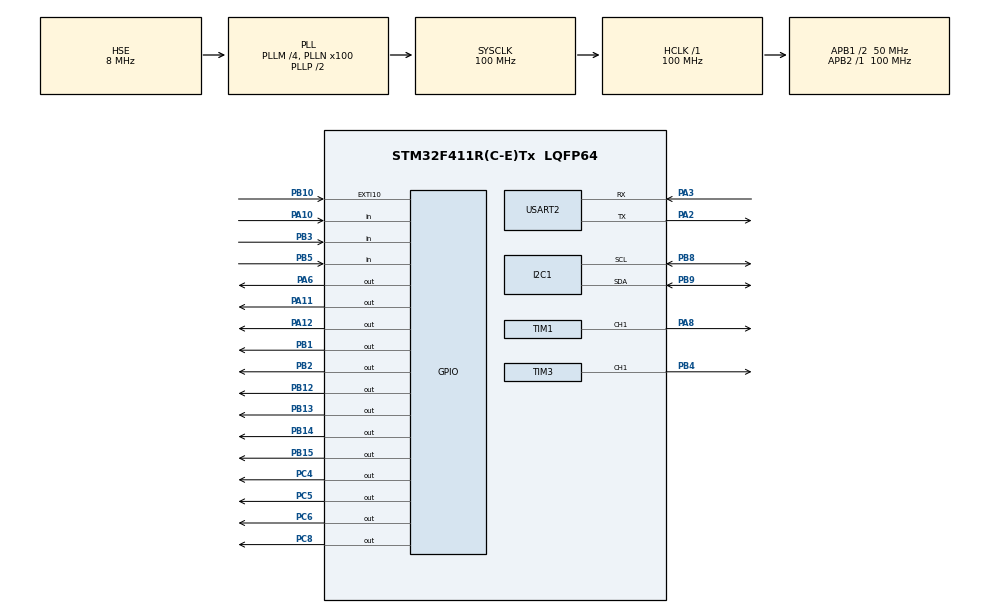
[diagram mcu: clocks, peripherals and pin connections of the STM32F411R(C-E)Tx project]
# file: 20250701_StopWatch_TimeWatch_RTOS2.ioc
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FREERTOS.Tasks01=defaultTask,0,128,StartDefaultTask,Default,NULL,Dynamic,NULL,NULL;ListenerTask,0,128,ListenerThread,Default,NULL,Dynamic,NULL,NULL;ControllerTask,0,128,ControllerThread,Default,NULL,Dynamic,NULL,NULL;PresenterTask,0,128,PresenterThread,Default,NULL,Dynamic,NULL,NULL
FREERTOS.configUSE_NEWLIB_REENTRANT=1
Mcu.Family=STM32F4
Mcu.Name=STM32F411R(C-E)Tx
Mcu.Package=LQFP64
NVIC.EXTI15_10_IRQn=true\:5\:0\:false\:false\:true\:true\:true\:true\:true
NVIC.PriorityGroup=NVIC_PRIORITYGROUP_4
NVIC.TIM1_TRG_COM_TIM11_IRQn=true\:15\:0\:false\:false\:true\:false\:false\:true\:true
NVIC.TIM2_IRQn=true\:5\:0\:false\:false\:true\:true\:true\:true\:true
NVIC.TIM4_IRQn=true\:5\:0\:false\:false\:true\:true\:true\:true\:true
NVIC.TimeBase=TIM1_TRG_COM_TIM11_IRQn
NVIC.TimeBaseIP=TIM11
NVIC.USART2_IRQn=true\:5\:0\:false\:false\:true\:true\:true\:true\:true
PA10.Signal=GPIO_Input
PA11.Signal=GPIO_Output
PA12.Signal=GPIO_Output
PA13.Mode=Serial_Wire
PA13.Signal=SYS_JTMS-SWDIO
PA14.Mode=Serial_Wire
PA14.Signal=SYS_JTCK-SWCLK
PA2.Mode=Asynchronous
PA2.Signal=USART2_TX
PA3.Mode=Asynchronous
PA3.Signal=USART2_RX
PA6.Signal=GPIO_Output
PA8.Signal=S_TIM1_CH1
PB1.Signal=GPIO_Output
PB10.GPIO_ModeDefaultEXTI=GPIO_MODE_IT_RISING_FALLING
PB10.Signal=GPXTI10
PB12.Signal=GPIO_Output
PB13.Signal=GPIO_Output
PB14.Signal=GPIO_Output
PB15.Signal=GPIO_Output
PB2.Signal=GPIO_Output
PB3.Signal=GPIO_Input
PB4.Signal=S_TIM3_CH1
PB5.Signal=GPIO_Input
PB8.Mode=I2C
PB8.Signal=I2C1_SCL
PB9.Mode=I2C
PB9.Signal=I2C1_SDA
PC4.Signal=GPIO_Output
PC5.Signal=GPIO_Output
PC6.Signal=GPIO_Output
PC8.Signal=GPIO_Output
PH0\ -\ OSC_IN.Mode=HSE-External-Oscillator
PH0\ -\ OSC_IN.Signal=RCC_OSC_IN
PH1\ -\ OSC_OUT.Mode=HSE-External-Oscillator
PH1\ -\ OSC_OUT.Signal=RCC_OSC_OUT
ProjectManager.HeapSize=0x200
ProjectManager.StackSize=0x400
ProjectManager.TargetToolchain=STM32CubeIDE
RCC.48MHZClocksFreq_Value=50000000
RCC.AHBFreq_Value=100000000
RCC.APB1CLKDivider=RCC_HCLK_DIV2
RCC.APB1Freq_Value=50000000
RCC.APB1TimFreq_Value=100000000
RCC.APB2Freq_Value=100000000
RCC.APB2TimFreq_Value=100000000
RCC.CortexFreq_Value=100000000
RCC.HCLKFreq_Value=100000000
RCC.HSE_VALUE=8000000
RCC.HSI_VALUE=16000000
RCC.LSE_VALUE=32768
RCC.PLLM=4
RCC.PLLN=100
RCC.PLLSourceVirtual=RCC_PLLSOURCE_HSE
RCC.SYSCLKFreq_VALUE=100000000
RCC.SYSCLKSource=RCC_SYSCLKSOURCE_PLLCLK
RCC.VCOOutputFreq_Value=200000000
SH.S_TIM1_CH1.0=TIM1_CH1,PWM Generation1 CH1
SH.S_TIM3_CH1.0=TIM3_CH1,PWM Generation1 CH1
TIM1.AutoReloadPreload=TIM_AUTORELOAD_PRELOAD_ENABLE
TIM1.Channel-PWM\ Generation1\ CH1=TIM_CHANNEL_1
TIM1.Period=100-1
TIM1.Prescaler=10000-1
TIM1.Pulse-PWM\ Generation1\ CH1=50-1
TIM2.Period=1000-1
TIM2.Prescaler=100-1
TIM3.AutoReloadPreload=TIM_AUTORELOAD_PRELOAD_ENABLE
TIM3.Channel-PWM\ Generation1\ CH1=TIM_CHANNEL_1
TIM3.Period=1000-1
TIM3.Prescaler=100-1
TIM4.AutoReloadPreload=TIM_AUTORELOAD_PRELOAD_ENABLE
TIM4.Period=1000-1
TIM4.Prescaler=100-1
TIM5.AutoReloadPreload=TIM_AUTORELOAD_PRELOAD_ENABLE
TIM5.Prescaler=100-1
USART2.VirtualMode=VM_ASYNC
VP_FREERTOS_VS_CMSIS_V1.Mode=CMSIS_V1
VP_SYS_VS_tim11.Mode=TIM11
VP_TIM2_VS_ClockSourceINT.Mode=Internal
VP_TIM3_VS_ClockSourceINT.Mode=Internal
VP_TIM4_VS_ClockSourceINT.Mode=Internal
VP_TIM5_VS_ClockSourceINT.Mode=Internal
board=custom

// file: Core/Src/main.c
/* USER CODE BEGIN Header */
/**
  ******************************************************************************
  * @file           : main.c
  * @brief          : Main program body
  ******************************************************************************
  * @attention
  *
  * Copyright (c) 2025 STMicroelectronics.
  * All rights reserved.
  *
  * This software is licensed under terms that can be found in the LICENSE file
  * in the root directory of this software component.
  * If no LICENSE file comes with this software, it is provided AS-IS.
  *
  ******************************************************************************
  */
/* USER CODE END Header */
#include "main.h"
#include "cmsis_os.h"
#include "i2c.h"
#include "tim.h"
#include "usart.h"
#include "gpio.h"

/* USER CODE BEGIN Includes */
#include "ap_main.h"
/* USER CODE END Includes */

void SystemClock_Config(void);
void MX_FREERTOS_Init(void);

int main(void)
{

  /* MCU Configuration--------------------------------------------------------*/

  /* Reset of all peripherals, Initializes the Flash interface and the Systick. */
  HAL_Init();

  /* Configure the system clock */
  SystemClock_Config();

  /* Initialize all configured peripherals */
  MX_GPIO_Init();
  MX_TIM2_Init();
  MX_USART2_UART_Init();
  MX_I2C1_Init();
  MX_TIM3_Init();
  MX_TIM1_Init();
  MX_TIM4_Init();
  MX_TIM5_Init();
  /* USER CODE BEGIN 2 */
  ap_init();
  /* USER CODE END 2 */

  /* Call init function for freertos objects (in cmsis_os2.c) */
  MX_FREERTOS_Init();

  /* Start scheduler */
  osKernelStart();

  /* We should never get here as control is now taken by the scheduler */

  /* Infinite loop */
  /* USER CODE BEGIN WHILE */
  while (1)
  {
	  ap_main();

    /* USER CODE END WHILE */

  }
}

void SystemClock_Config(void)
{
  RCC_OscInitTypeDef RCC_OscInitStruct = {0};
  RCC_ClkInitTypeDef RCC_ClkInitStruct = {0};

  /** Configure the main internal regulator output voltage
  */
  __HAL_RCC_PWR_CLK_ENABLE();
  __HAL_PWR_VOLTAGESCALING_CONFIG(PWR_REGULATOR_VOLTAGE_SCALE1);

  /** Initializes the RCC Oscillators according to the specified parameters
  * in the RCC_OscInitTypeDef structure.
  */
  RCC_OscInitStruct.OscillatorType = RCC_OSCILLATORTYPE_HSE;
  RCC_OscInitStruct.HSEState = RCC_HSE_ON;
  RCC_OscInitStruct.PLL.PLLState = RCC_PLL_ON;
  RCC_OscInitStruct.PLL.PLLSource = RCC_PLLSOURCE_HSE;
  RCC_OscInitStruct.PLL.PLLM = 4;
  RCC_OscInitStruct.PLL.PLLN = 100;
  RCC_OscInitStruct.PLL.PLLP = RCC_PLLP_DIV2;
  RCC_OscInitStruct.PLL.PLLQ = 4;
  if (HAL_RCC_OscConfig(&RCC_OscInitStruct) != HAL_OK)
  {
    Error_Handler();
  }

  /** Initializes the CPU, AHB and APB buses clocks
  */
  RCC_ClkInitStruct.ClockType = RCC_CLOCKTYPE_HCLK|RCC_CLOCKTYPE_SYSCLK
                              |RCC_CLOCKTYPE_PCLK1|RCC_CLOCKTYPE_PCLK2;
  RCC_ClkInitStruct.SYSCLKSource = RCC_SYSCLKSOURCE_PLLCLK;
  RCC_ClkInitStruct.AHBCLKDivider = RCC_SYSCLK_DIV1;
  RCC_ClkInitStruct.APB1CLKDivider = RCC_HCLK_DIV2;
  RCC_ClkInitStruct.APB2CLKDivider = RCC_HCLK_DIV1;

  if (HAL_RCC_ClockConfig(&RCC_ClkInitStruct, FLASH_LATENCY_3) != HAL_OK)
  {
    Error_Handler();
  }
}

void HAL_TIM_PeriodElapsedCallback(TIM_HandleTypeDef *htim)
{
  if (htim->Instance == TIM11)
  {
    HAL_IncTick();
  }

  if(htim->Instance == TIM2) {
     FND_DispDataCallBack();

     TimeWatch_IncTimeCallBack();
     StopWatch_IncTimeCallBack();
  }
}

void Error_Handler(void)
{
  __disable_irq();
  while (1)
  {
  }
}

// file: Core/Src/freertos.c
/* USER CODE BEGIN Header */
/**
  ******************************************************************************
  * File Name          : freertos.c
  * Description        : Code for freertos applications
  ******************************************************************************
  * @attention
  *
  * Copyright (c) 2025 STMicroelectronics.
  * All rights reserved.
  *
  * This software is licensed under terms that can be found in the LICENSE file
  * in the root directory of this software component.
  * If no LICENSE file comes with this software, it is provided AS-IS.
  *
  ******************************************************************************
  */
/* USER CODE END Header */

#include "FreeRTOS.h"
#include "task.h"
#include "main.h"
#include "cmsis_os.h"

osThreadId defaultTaskHandle;
osThreadId ListenerTaskHandle;
osThreadId ControllerTaskHandle;
osThreadId PresenterTaskHandle;

/* USER CODE BEGIN FunctionPrototypes */
//void HAL_TIM_PeriodElapsedCallback(TIM_HandleTypeDef *htim)
//{
//   if(htim->Instance == TIM2) {
//      FND_DispDataCallBack();
//
//      TimeWatch_IncTimeCallBack();
//      StopWatch_IncTimeCallBack();
//   }
//}

//void HAL_UART_RxCpltCallback(UART_HandleTypeDef *huart)
//{
//   if (huart->Instance == USART2) {
//      Listener_UartCallBack();
//   }
//}

/* USER CODE END FunctionPrototypes */

void StartDefaultTask(void const * argument);
void ListenerThread(void const * argument);
void ControllerThread(void const * argument);
void PresenterThread(void const * argument);

void MX_FREERTOS_Init(void); /* (MISRA C 2004 rule 8.1) */

/* GetIdleTaskMemory prototype (linked to static allocation support) */
void vApplicationGetIdleTaskMemory( StaticTask_t **ppxIdleTaskTCBBuffer, StackType_t **ppxIdleTaskStackBuffer, uint32_t *pulIdleTaskStackSize );

/* USER CODE BEGIN GET_IDLE_TASK_MEMORY */
static StaticTask_t xIdleTaskTCBBuffer;
static StackType_t xIdleStack[configMINIMAL_STACK_SIZE];

void vApplicationGetIdleTaskMemory( StaticTask_t **ppxIdleTaskTCBBuffer, StackType_t **ppxIdleTaskStackBuffer, uint32_t *pulIdleTaskStackSize )
{
  *ppxIdleTaskTCBBuffer = &xIdleTaskTCBBuffer;
  *ppxIdleTaskStackBuffer = &xIdleStack[0];
  *pulIdleTaskStackSize = configMINIMAL_STACK_SIZE;
  /* place for user code */
}
/* USER CODE END GET_IDLE_TASK_MEMORY */

void MX_FREERTOS_Init(void) {
  /* USER CODE BEGIN Init */
	Model_Init();
  /* USER CODE END Init */

  /* Create the thread(s) */
  /* definition and creation of defaultTask */
  osThreadDef(defaultTask, StartDefaultTask, osPriorityNormal, 0, 128);
  defaultTaskHandle = osThreadCreate(osThread(defaultTask), NULL);

  /* definition and creation of ListenerTask */
  osThreadDef(ListenerTask, ListenerThread, osPriorityNormal, 0, 128);
  ListenerTaskHandle = osThreadCreate(osThread(ListenerTask), NULL);

  /* definition and creation of ControllerTask */
  osThreadDef(ControllerTask, ControllerThread, osPriorityNormal, 0, 128);
  ControllerTaskHandle = osThreadCreate(osThread(ControllerTask), NULL);

  /* definition and creation of PresenterTask */
  osThreadDef(PresenterTask, PresenterThread, osPriorityNormal, 0, 128);
  PresenterTaskHandle = osThreadCreate(osThread(PresenterTask), NULL);

}

void StartDefaultTask(void const * argument)
{
  for(;;)
  {
    osDelay(1);
  }
}

void ListenerThread(void const * argument)
{
  /* USER CODE BEGIN ListenerThread */
  /* Infinite loop */
	Listener_Init();
  for(;;)
  {
	  Listener_Excute();
    osDelay(1);
  }
  /* USER CODE END ListenerThread */
}

void ControllerThread(void const * argument)
{
  /* USER CODE BEGIN ControllerThread */

  /* Infinite loop */
  for(;;)
  {
	Controller_Excute();
    osDelay(1);
  }
  /* USER CODE END ControllerThread */
}

void PresenterThread(void const * argument)
{
  /* USER CODE BEGIN PresenterThread */
  /* Infinite loop */
	Presenter_Init();
  for(;;)
  {
	Presenter_Excute();
    osDelay(1);
  }
  /* USER CODE END PresenterThread */
}
